AUTOSAR XML (schema 4.0)
standard types defined: float32, float64, sint16, sint32, sint8, uint16, uint32, uint8, void, boolean
package /ImplDataTypes
  6 x impl type, all with category=TYPE_REFERENCE, type-emitter=RTE:
    IoPositionSensorReadingType: implementation-data-type=uint8
    IoWeightSensorReadingType: implementation-data-type=uint8
    MultiStateBtnType: implementation-data-type=uint8
    SensorPositionType: implementation-data-type=uint8
    SensorWeightType: implementation-data-type=MultiStateBtnType
    StepMotorStepType: implementation-data-type=uint8
package /MappingSets
  data type mapping set MappingSet: mode-request-type-map{implementation-data-type=uint8, mode-group=SeatCtrlMode}
package /PortInterfaces/ClientServer
  6 x client server interface:
    CsIf_IoGetSensorPosition
      operation IOGet
        arg IoWeightPositionReadingType_position: type=IoPositionSensorReadingType, direction=OUT
    CsIf_IoGetSensorWeight
      operation IOGet
        arg IoWeightSensorReadingType_weight: type=IoWeightSensorReadingType, direction=OUT
    CsIf_IoSetMotor
      operation IOSetForward
      operation IOSetReverse
    CsIf_PositionSensor
      operation GetPosition
        arg SensorPositionType_position: type=SensorPositionType, direction=OUT
    CsIf_StepMotor
      operation Move
        arg step: type=StepMotorStepType, direction=IN
    CsIf_WeightSensor
      operation GetWeight
        arg SensorWeightType_weight: type=SensorWeightType, direction=OUT
package /PortInterfaces/ModeSwitch
  mode switch interface MsIf_SeatCtrlMode
    mode group SeatCtrlMode: type=SeatCtrlMode
  mode declaration group SeatCtrlMode: category=ALPHABETIC_ORDER, initial-mode=INIT, on-transition-value=255
    mode AUTO
    mode INIT
    mode MANUAL
package /PortInterfaces/SenderReceiver
  sender receiver interface SrIf_SeatCtrlBtns
    data HeightBtnState: type=MultiStateBtnType
    data InclineBtnState: type=MultiStateBtnType
    data SlideBtnState: type=MultiStateBtnType
  sender receiver interface SrIf_SeatCtrlData
    data Height: type=uint8
    data Incline: type=uint8
    data Slide: type=uint8
  sender receiver interface SrIf_SeatModeBtn
    data SeatModeBtn: type=uint8
package /SoftwareComponents
  10 x swc implementation, all with programming-language=C, sw-version=1.0.0, vendor-id=255:
    Impl_IoHwAbs: behavior=Ibhv_IoHwAbs
      code-descriptors:
        code Code: artifact-descriptors=autosar-engineering-object={short-label=SWC.c, category=SWSRC}
      resource consumption ResourceConsumption
    Impl_SWC_HMI: behavior=Ibhv_SWC_HMI
      code-descriptors:
        code Code: artifact-descriptors=autosar-engineering-object={short-label=SWC.c, category=SWSRC}
      resource consumption ResourceConsumption
    Impl_SWC_HeightMotor: behavior=Ibhv_SWC_HeightMotor
      code-descriptors:
        code Code: artifact-descriptors=autosar-engineering-object={short-label=SWC.c, category=SWSRC}
      resource consumption ResourceConsumption
    Impl_SWC_HeightSensor: behavior=Ibhv_SWC_HeightSensor
      code-descriptors:
        code Code: artifact-descriptors=autosar-engineering-object={short-label=SWC.c, category=SWSRC}
      resource consumption ResourceConsumption
    Impl_SWC_InclineMotor: behavior=Ibhv_SWC_InclineMotor
      code-descriptors:
        code Code: artifact-descriptors=autosar-engineering-object={short-label=SWC.c, category=SWSRC}
      resource consumption ResourceConsumption
    Impl_SWC_InclineSensor: behavior=Ibhv_SWC_InclineSensor
      code-descriptors:
        code Code: artifact-descriptors=autosar-engineering-object={short-label=SWC.c, category=SWSRC}
      resource consumption ResourceConsumption
    Impl_SWC_SeatManager: behavior=Ibhv_SWC_SeatManager
      code-descriptors:
        code Code: artifact-descriptors=autosar-engineering-object={short-label=SWC.c, category=SWSRC}
      resource consumption ResourceConsumption
    Impl_SWC_SlideMotor: behavior=Ibhv_SWC_SlideMotor
      code-descriptors:
        code Code: artifact-descriptors=autosar-engineering-object={short-label=SWC.c, category=SWSRC}
      resource consumption ResourceConsumption
    Impl_SWC_SlideSensor: behavior=Ibhv_SWC_SlideSensor
      code-descriptors:
        code Code: artifact-descriptors=autosar-engineering-object={short-label=SWC.c, category=SWSRC}
      resource consumption ResourceConsumption
    Impl_SWC_WeightSensor: behavior=Ibhv_SWC_WeightSensor
      code-descriptors:
        code Code: artifact-descriptors=autosar-engineering-object={short-label=SWC.c, category=SWSRC}
      resource consumption ResourceConsumption
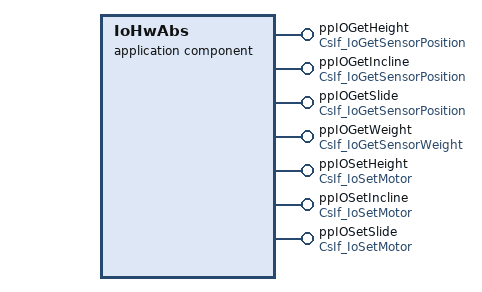
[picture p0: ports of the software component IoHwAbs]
  application sw component type IoHwAbs
    7 x provide port:
      ppIOGetHeight: provided-interface=CsIf_IoGetSensorPosition
      ppIOGetIncline: provided-interface=CsIf_IoGetSensorPosition
      ppIOGetSlide: provided-interface=CsIf_IoGetSensorPosition
      ppIOGetWeight: provided-interface=CsIf_IoGetSensorWeight
      ppIOSetHeight: provided-interface=CsIf_IoSetMotor
      ppIOSetIncline: provided-interface=CsIf_IoSetMotor
      ppIOSetSlide: provided-interface=CsIf_IoSetMotor
    behavior Ibhv_IoHwAbs: data-type-mapping=MappingSet, handle-termination-and-restart=NO-SUPPORT
      10 x operation invoked event:
        OIE_ppIOGetHeight_IOGet: start-on-event=IoHwAbs_ECUGet_Height, operation=ppIOGetHeight.IOGet
        OIE_ppIOGetIncline_IOGet: start-on-event=IoHwAbs_ECUGet_Incline, operation=ppIOGetIncline.IOGet
        OIE_ppIOGetSlide_IOGet: start-on-event=IoHwAbs_ECUGet_Slide, operation=ppIOGetSlide.IOGet
        OIE_ppIOGetWeight_IOGet: start-on-event=IoHwAbs_ECUGet_Weight, operation=ppIOGetWeight.IOGet
        OIE_ppIOSetHeight_IOSetForward: start-on-event=IoHwAbs_ECUSetForward_Height, operation=ppIOSetHeight.IOSetForward
        OIE_ppIOSetHeight_IOSetReverse: start-on-event=IoHwAbs_ECUSetReverse_Height, operation=ppIOSetHeight.IOSetReverse
        OIE_ppIOSetIncline_IOSetForward: start-on-event=IoHwAbs_ECUSetForward_Incline, operation=ppIOSetIncline.IOSetForward
        OIE_ppIOSetIncline_IOSetReverse: start-on-event=IoHwAbs_ECUSetReverse_Incline, operation=ppIOSetIncline.IOSetReverse
        OIE_ppIOSetSlide_IOSetForward: start-on-event=IoHwAbs_ECUSetForward_Slide, operation=ppIOSetSlide.IOSetForward
        OIE_ppIOSetSlide_IOSetReverse: start-on-event=IoHwAbs_ECUSetReverse_Slide, operation=ppIOSetSlide.IOSetReverse
      10 x runnable:
        IoHwAbs_ECUGet_Height
        IoHwAbs_ECUGet_Incline
        IoHwAbs_ECUGet_Slide
        IoHwAbs_ECUGet_Weight
        IoHwAbs_ECUSetForward_Height
        IoHwAbs_ECUSetForward_Incline
        IoHwAbs_ECUSetForward_Slide
        IoHwAbs_ECUSetReverse_Height
        IoHwAbs_ECUSetReverse_Incline
        IoHwAbs_ECUSetReverse_Slide
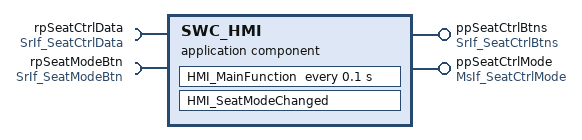
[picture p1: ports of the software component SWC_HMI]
  application sw component type SWC_HMI
    provide port ppSeatCtrlBtns: provided-interface=SrIf_SeatCtrlBtns
    provide port ppSeatCtrlMode: provided-interface=MsIf_SeatCtrlMode
    require port rpSeatCtrlData: required-interface=SrIf_SeatCtrlData
    require port rpSeatModeBtn: required-interface=SrIf_SeatModeBtn
    behavior Ibhv_SWC_HMI: data-type-mapping=MappingSet, handle-termination-and-restart=NO-SUPPORT
      data received event DRE_rpSeatModeBtn_SeatModeBtn: start-on-event=HMI_SeatModeChanged, data=rpSeatModeBtn.SeatModeBtn
      timing event TE_HMI_MainFunction_100ms: start-on-event=HMI_MainFunction, period=0.1
      runnable HMI_MainFunction
        data-receive-point-by-arguments:
          access DRP_rpSeatCtrlData_DE_Height: accessed-variable=rpSeatCtrlData.Height
          access DRP_rpSeatCtrlData_DE_Incline: accessed-variable=rpSeatCtrlData.Incline
          access DRP_rpSeatCtrlData_DE_Slide: accessed-variable=rpSeatCtrlData.Slide
        data-send-points:
          access DSP_ppSeatCtrlBtns_DE_HeightBtnState: accessed-variable=ppSeatCtrlBtns.HeightBtnState
          access DSP_ppSeatCtrlBtns_DE_InclineBtnState: accessed-variable=ppSeatCtrlBtns.InclineBtnState
          access DSP_ppSeatCtrlBtns_DE_SlideBtnState: accessed-variable=ppSeatCtrlBtns.SlideBtnState
      runnable HMI_SeatModeChanged
        data-receive-point-by-arguments:
          access DRP_rpSeatModeBtn_SeatModeBtn: accessed-variable=rpSeatModeBtn.SeatModeBtn
        mode switch point MSP_ppSeatCtrlMode_ppSeatCtrlMode: mode-group=ppSeatCtrlMode.SeatCtrlMode
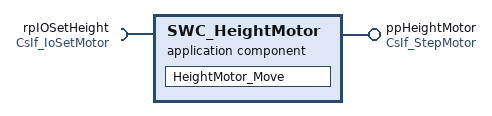
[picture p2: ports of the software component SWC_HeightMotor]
  application sw component type SWC_HeightMotor
    provide port ppHeightMotor: provided-interface=CsIf_StepMotor
    require port rpIOSetHeight: required-interface=CsIf_IoSetMotor
    behavior Ibhv_SWC_HeightMotor: data-type-mapping=MappingSet, handle-termination-and-restart=NO-SUPPORT
      operation invoked event OIE_ppHeightMotor_Move: start-on-event=HeightMotor_Move, operation=ppHeightMotor.Move
      runnable HeightMotor_Move
        sync call SCP_rpIOSetHeight_IOSetForward: operation=rpIOSetHeight.IOSetForward, timeout=0.0
        sync call SCP_rpIOSetHeight_IOSetReverse: operation=rpIOSetHeight.IOSetReverse, timeout=0.0
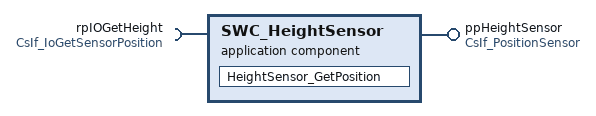
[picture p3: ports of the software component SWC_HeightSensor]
  application sw component type SWC_HeightSensor
    provide port ppHeightSensor: provided-interface=CsIf_PositionSensor
    require port rpIOGetHeight: required-interface=CsIf_IoGetSensorPosition
    behavior Ibhv_SWC_HeightSensor: data-type-mapping=MappingSet, handle-termination-and-restart=NO-SUPPORT
      operation invoked event OIE_ppHeightSensor_GetPosition: start-on-event=HeightSensor_GetPosition, operation=ppHeightSensor.GetPosition
      runnable HeightSensor_GetPosition
        sync call SCP_rpIOGetHeight_IOGet: operation=rpIOGetHeight.IOGet, timeout=0.0
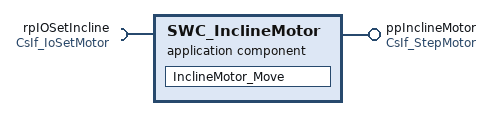
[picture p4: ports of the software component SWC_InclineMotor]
  application sw component type SWC_InclineMotor
    provide port ppInclineMotor: provided-interface=CsIf_StepMotor
    require port rpIOSetIncline: required-interface=CsIf_IoSetMotor
    behavior Ibhv_SWC_InclineMotor: data-type-mapping=MappingSet, handle-termination-and-restart=NO-SUPPORT
      operation invoked event OIE_ppInclineMotor_Move: start-on-event=InclineMotor_Move, operation=ppInclineMotor.Move
      runnable InclineMotor_Move
        sync call SCP_rpIOSetIncline_IOSetForward: operation=rpIOSetIncline.IOSetForward, timeout=0.0
        sync call SCP_rpIOSetIncline_IOSetReverse: operation=rpIOSetIncline.IOSetReverse, timeout=0.0
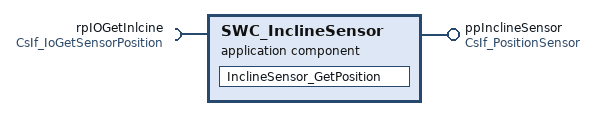
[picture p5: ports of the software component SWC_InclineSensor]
  application sw component type SWC_InclineSensor
    provide port ppInclineSensor: provided-interface=CsIf_PositionSensor
    require port rpIOGetInlcine: required-interface=CsIf_IoGetSensorPosition
    behavior Ibhv_SWC_InclineSensor: data-type-mapping=MappingSet, handle-termination-and-restart=NO-SUPPORT
      operation invoked event OIE_ppInclineSensor_GetPosition: start-on-event=InclineSensor_GetPosition, operation=ppInclineSensor.GetPosition
      runnable InclineSensor_GetPosition
        sync call SCP_rpIOGetInlcine_IOGet: operation=rpIOGetInlcine.IOGet, timeout=0.0
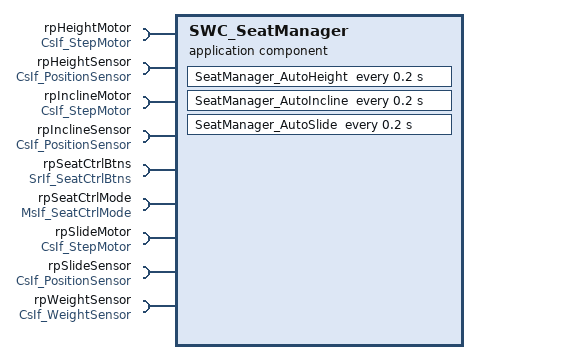
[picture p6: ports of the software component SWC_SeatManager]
  application sw component type SWC_SeatManager
    9 x require port:
      rpHeightMotor: required-interface=CsIf_StepMotor
      rpHeightSensor: required-interface=CsIf_PositionSensor
      rpInclineMotor: required-interface=CsIf_StepMotor
      rpInclineSensor: required-interface=CsIf_PositionSensor
      rpSeatCtrlBtns: required-interface=SrIf_SeatCtrlBtns
      rpSeatCtrlMode: required-interface=MsIf_SeatCtrlMode
      rpSlideMotor: required-interface=CsIf_StepMotor
      rpSlideSensor: required-interface=CsIf_PositionSensor
      rpWeightSensor: required-interface=CsIf_WeightSensor
    behavior Ibhv_SWC_SeatManager: data-type-mapping=MappingSet, handle-termination-and-restart=NO-SUPPORT
      data received event DRE_rpSeatCtrlBtns_DE_HeightBtnState: start-on-event=SeatManager_SetHeight, data=rpSeatCtrlBtns.HeightBtnState
      data received event DRE_rpSeatCtrlBtns_DE_InclineBtnState: start-on-event=SeatManager_SetIncline, data=rpSeatCtrlBtns.InclineBtnState
      data received event DRE_rpSeatCtrlBtns_DE_SlideBtnState: start-on-event=SeatManager_SetSlide, data=rpSeatCtrlBtns.SlideBtnState
      timing event TE_SeatManager_AutoHeight_200ms: start-on-event=SeatManager_AutoHeight, period=0.2
      timing event TE_SeatManager_AutoIncline_200ms: start-on-event=SeatManager_AutoIncline, period=0.2
      timing event TE_SeatManager_AutoSlide_200ms: start-on-event=SeatManager_AutoSlide, period=0.2
      6 x runnable:
        SeatManager_AutoHeight
          sync call SCP_rpHeightMotor_Move: operation=rpHeightMotor.Move, timeout=0.0
          sync call SCP_rpHeightSensor_GetPosition: operation=rpHeightSensor.GetPosition, timeout=0.0
          sync call SCP_rpWeightSensor_GetWeight: operation=rpWeightSensor.GetWeight, timeout=0.0
        SeatManager_AutoIncline
          sync call SCP_rpInclineMotor_Move: operation=rpInclineMotor.Move, timeout=0.0
          sync call SCP_rpInclineSensor_GetPosition: operation=rpInclineSensor.GetPosition, timeout=0.0
          sync call SCP_rpWeightSensor_GetWeight: operation=rpWeightSensor.GetWeight, timeout=0.0
        SeatManager_AutoSlide
          sync call SCP_rpSlideMotor_Move: operation=rpSlideMotor.Move, timeout=0.0
          sync call SCP_rpSlideSensor_GetPosition: operation=rpSlideSensor.GetPosition, timeout=0.0
          sync call SCP_rpWeightSensor_GetWeight: operation=rpWeightSensor.GetWeight, timeout=0.0
        SeatManager_SetHeight
          data-receive-point-by-arguments:
            access DRP_rpSeatCtrlBtns_DE_HeightBtnState: accessed-variable=rpSeatCtrlBtns.HeightBtnState
          sync call SCP_rpHeightMotor_Move: operation=rpHeightMotor.Move, timeout=0.0
        SeatManager_SetIncline
          data-receive-point-by-arguments:
            access DRP_rpSeatCtrlBtns_DE_InclineBtnState: accessed-variable=rpSeatCtrlBtns.InclineBtnState
          sync call SCP_rpInclineMotor_Move: operation=rpInclineMotor.Move, timeout=0.0
        SeatManager_SetSlide
          data-receive-point-by-arguments:
            access DRP_rpSeatCtrlBtns_DE_SlideBtnState: accessed-variable=rpSeatCtrlBtns.SlideBtnState
          sync call SCP_rpSlideMotor_Move: operation=rpSlideMotor.Move, timeout=0.0
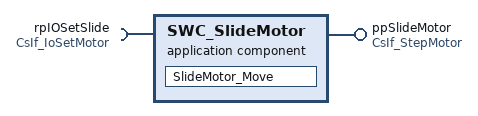
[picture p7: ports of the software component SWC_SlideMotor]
  application sw component type SWC_SlideMotor
    provide port ppSlideMotor: provided-interface=CsIf_StepMotor
    require port rpIOSetSlide: required-interface=CsIf_IoSetMotor
    behavior Ibhv_SWC_SlideMotor: data-type-mapping=MappingSet, handle-termination-and-restart=NO-SUPPORT
      operation invoked event OIE_ppSlideMotor_Move: start-on-event=SlideMotor_Move, operation=ppSlideMotor.Move
      runnable SlideMotor_Move
        sync call SCP_rpIOSetSlide_IOSetForward: operation=rpIOSetSlide.IOSetForward, timeout=0.0
        sync call SCP_rpIOSetSlide_IOSetReverse: operation=rpIOSetSlide.IOSetReverse, timeout=0.0
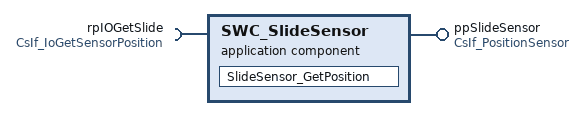
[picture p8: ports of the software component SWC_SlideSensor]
  application sw component type SWC_SlideSensor
    provide port ppSlideSensor: provided-interface=CsIf_PositionSensor
    require port rpIOGetSlide: required-interface=CsIf_IoGetSensorPosition
    behavior Ibhv_SWC_SlideSensor: data-type-mapping=MappingSet, handle-termination-and-restart=NO-SUPPORT
      operation invoked event OIE_ppSlideSensor_GetPosition: start-on-event=SlideSensor_GetPosition, operation=ppSlideSensor.GetPosition
      runnable SlideSensor_GetPosition
        sync call SCP_rpIOGetSlide_IOGet: operation=rpIOGetSlide.IOGet, timeout=0.0
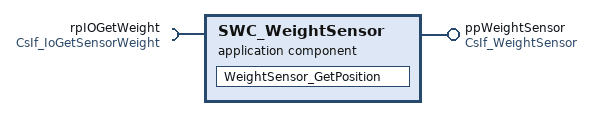
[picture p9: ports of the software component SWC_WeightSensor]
  application sw component type SWC_WeightSensor
    provide port ppWeightSensor: provided-interface=CsIf_WeightSensor
    require port rpIOGetWeight: required-interface=CsIf_IoGetSensorWeight
    behavior Ibhv_SWC_WeightSensor: data-type-mapping=MappingSet, handle-termination-and-restart=NO-SUPPORT
      operation invoked event OIE_ppWeightSensor_GetWeight: start-on-event=WeightSensor_GetPosition, operation=ppWeightSensor.GetWeight
      runnable WeightSensor_GetPosition
        sync call SCP_rpIOGetWeight_IOGet: operation=rpIOGetWeight.IOGet, timeout=0.0
package /Compositions
  composition sw component type Task1Composition
    10 x component:
      IoHwAbs: type=IoHwAbs
      SWC_HMI: type=SWC_HMI
      SWC_HeightMotor: type=SWC_HeightMotor
      SWC_HeightSensor: type=SWC_HeightSensor
      SWC_InclineMotor: type=SWC_InclineMotor
      SWC_InclineSensor: type=SWC_InclineSensor
      SWC_SeatManager: type=SWC_SeatManager
      SWC_SlideMotor: type=SWC_SlideMotor
      SWC_SlideSensor: type=SWC_SlideSensor
      SWC_WeightSensor: type=SWC_WeightSensor
    connect IoHwAbs.ppIOGetHeight -> SWC_HeightSensor.rpIOGetHeight
    connect IoHwAbs.ppIOGetIncline -> SWC_InclineSensor.rpIOGetInlcine
    connect IoHwAbs.ppIOGetSlide -> SWC_SlideSensor.rpIOGetSlide
    connect IoHwAbs.ppIOGetWeight -> SWC_WeightSensor.rpIOGetWeight
    connect IoHwAbs.ppIOSetHeight -> SWC_HeightMotor.rpIOSetHeight
    connect IoHwAbs.ppIOSetIncline -> SWC_InclineMotor.rpIOGetIncline
    connect IoHwAbs.ppIOSetSlide -> SWC_SlideMotor.rpIOGetSlide
    connect SWC_HMI.ppSeatCtrlBtns -> SWC_SeatManager.rpSeatCtrlBtns
    connect SWC_HMI.ppSeatCtrlMode -> SWC_SeatManager.rpSeatCtrlMode
    connect SWC_HeightMotor.ppHeightMotor -> SWC_SeatManager.rpHeightMotor
    connect SWC_HeightSensor.ppHeightSensor -> SWC_SeatManager.rpHeightSensor
    connect SWC_InclineMotor.ppInclineMotor -> SWC_SeatManager.rpInclineMotor
    connect SWC_InclineSensor.ppInclineSensor -> SWC_SeatManager.rpInclineSensor
    connect SWC_SlideMotor.ppSlideMotor -> SWC_SeatManager.rpSlideMotor
    connect SWC_SlideSensor.ppSlideSensor -> SWC_SeatManager.rpSlideSensor
    connect SWC_WeightSensor.ppWeightSensor -> SWC_SeatManager.rpWeightSensor
